# rstctl register map
Vendor: Texas Instruments
Peripheral module from a debugger description file (folder MSP432).
Registers are 32-bit, read-write, no defined reset value unless marked. A register's access mark holds for its fields unless they carry their own. Offsets are as the file gives them; lines under a group give offsets from that group; [hi:lo] are bit positions; {n}, {i} and the like mark numbered series; 'fields as' and 'values as' point back to an identical list; <NAME> marks a mode.

## RSTCTL
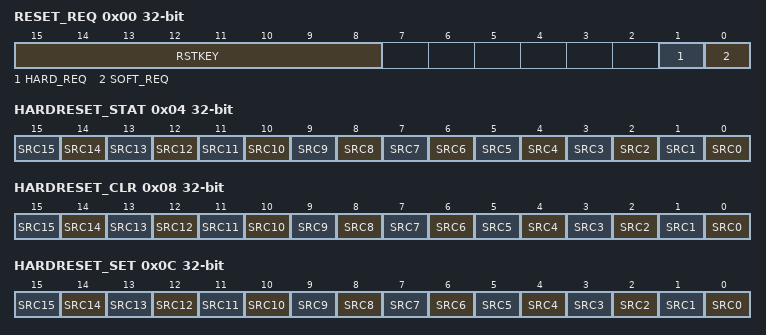
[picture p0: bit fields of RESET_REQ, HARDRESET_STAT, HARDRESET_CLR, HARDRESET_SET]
0x00 RESET_REQ — Reset Request Register
  [15:8] RSTKEY — Must be written with 69h to enable writes to bits 1-0 (in the s
  [1] HARD_REQ — If written with 1, generates a Hard Reset request to the Reset
  [0] SOFT_REQ — If written with 1, generates a Soft Reset request to the Reset
0x04 HARDRESET_STAT — Hard Reset Status Register
  [n] SRC{n} (n=0..15) — If 1, indicates that SRC{n} was the source of the Hard Reset
0x08 HARDRESET_CLR — Hard Reset Status Clear Register
  [n] SRC{n} (n=0..15) — Write 1 clears the corresponding bit in the RSTCTL_HARDRESET_ST
0x0C HARDRESET_SET — Hard Reset Status Set Register
  [n] SRC{n} (n=0..15) — Write 1 sets the corresponding bit in the RSTCTL_HARDRESET_STAT
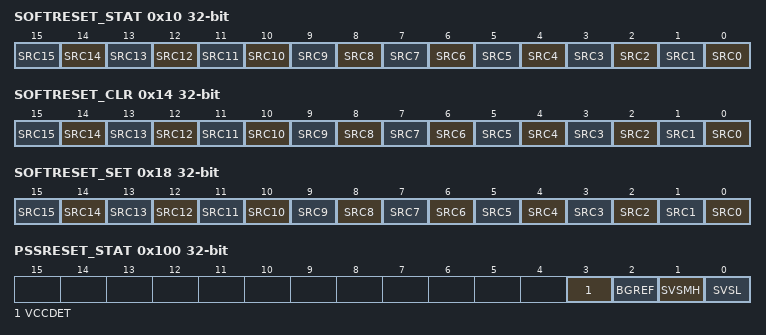
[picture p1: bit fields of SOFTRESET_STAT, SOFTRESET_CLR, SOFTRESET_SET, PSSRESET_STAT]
0x10 SOFTRESET_STAT — Soft Reset Status Register
  [n] SRC{n} (n=0..15) — If 1, indicates that SRC{n} was the source of the Soft Reset
0x14 SOFTRESET_CLR — Soft Reset Status Clear Register
  [n] SRC{n} (n=0..15) — Write 1 clears the corresponding bit in the RSTCTL_SOFTRESET_ST
0x18 SOFTRESET_SET — Soft Reset Status Set Register
  [n] SRC{n} (n=0..15) — Write 1 sets the corresponding bit in the RSTCTL_SOFTRESET_STAT
0x100 PSSRESET_STAT — PSS Reset Status Register
  [3] VCCDET — Indicates if POR was caused by a VCCDET trip condition in the P
  [2] BGREF — Indicates if POR was caused by a BGREF not okay condition in th
  [1] SVSMH — Indicates if POR was caused by an SVSMH trip condition int the
  [0] SVSL — Indicates if POR was caused by an SVSL trip condition in the PS
0x104 PSSRESET_CLR — PSS Reset Status Clear Register
  [0] CLR — Write 1 clears all PSS Reset Flags in the RSTCTL_PSSRESET_STAT
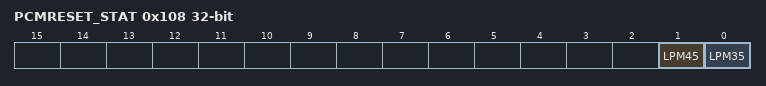
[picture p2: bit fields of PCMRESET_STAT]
0x108 PCMRESET_STAT — PCM Reset Status Register
  [1] LPM45 — Indicates if POR was caused by PCM due to an exit from LPM4.5
  [0] LPM35 — Indicates if POR was caused by PCM due to an exit from LPM3.5
0x10C PCMRESET_CLR — PCM Reset Status Clear Register
  [0] CLR — Write 1 clears all PCM Reset Flags in the RSTCTL_PCMRESET_STAT
0x110 PINRESET_STAT — Pin Reset Status Register
  [0] RSTNMI — Indicates if POR was caused by RSTn/NMI pin based reset event i
0x114 PINRESET_CLR — Pin Reset Status Clear Register
  [0] CLR — Write 1 clears the RSTn/NMI Pin Reset Flag in RSTCTL_PINRESET_S
0x118 REBOOTRESET_STAT — Reboot Reset Status Register
  [0] REBOOT — Indicates if Reboot reset was caused by the SYSCTL module.
0x11C REBOOTRESET_CLR — Reboot Reset Status Clear Register
  [0] CLR — Write 1 clears the Reboot Reset Flag in RSTCTL_REBOOTRESET_STAT
